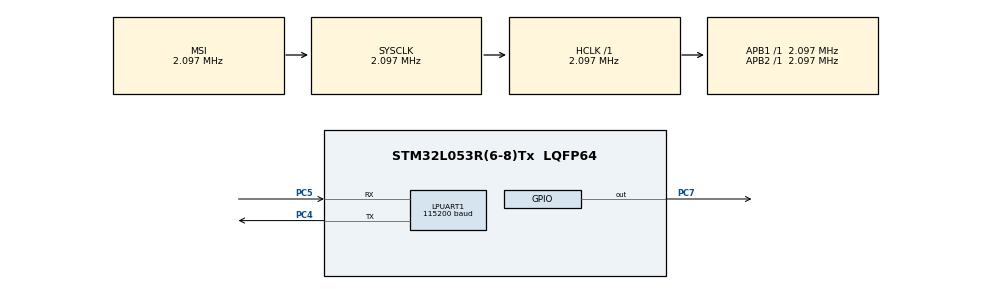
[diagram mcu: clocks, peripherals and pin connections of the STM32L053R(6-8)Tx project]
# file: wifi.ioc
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LPUART1.BaudRate=115200
LPUART1.WordLength=UART_WORDLENGTH_8B
Mcu.Family=STM32L0
Mcu.Name=STM32L053R(6-8)Tx
Mcu.Package=LQFP64
PC4.Mode=Asynchronous
PC4.Signal=LPUART1_TX
PC5.Mode=Asynchronous
PC5.Signal=LPUART1_RX
PC7.Signal=GPIO_Output
ProjectManager.HeapSize=0x200
ProjectManager.StackSize=0x400
ProjectManager.TargetToolchain=STM32CubeIDE
RCC.AHBFreq_Value=2097000
RCC.APB1Freq_Value=2097000
RCC.APB1TimFreq_Value=2097000
RCC.APB2Freq_Value=2097000
RCC.APB2TimFreq_Value=2097000
RCC.HSE_VALUE=8000000
RCC.HSI16_VALUE=16000000
RCC.HSI48_VALUE=48000000
RCC.HSI_VALUE=16000000
RCC.LSE_VALUE=32768
RCC.MSI_VALUE=2097000
RCC.SYSCLKFreq_VALUE=2097000
RCC.VCOOutputFreq_Value=48000000
board=custom

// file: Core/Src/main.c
/* USER CODE BEGIN Header */
/**
  ******************************************************************************
  * @file           : main.c
  * @brief          : Main program body
  ******************************************************************************
  * @attention
  *
  * Copyright (c) 2026 STMicroelectronics.
  * All rights reserved.
  *
  * This software is licensed under terms that can be found in the LICENSE file
  * in the root directory of this software component.
  * If no LICENSE file comes with this software, it is provided AS-IS.
  *
  ******************************************************************************
  */
/* USER CODE END Header */
#include "main.h"

/* USER CODE BEGIN Includes */
//#include <stdlib.h>
//#include <stdio.h>
//#include <string.h>
#include <stdio.h>
#include <string.h>

/* USER CODE END Includes */

UART_HandleTypeDef hlpuart1;

void SystemClock_Config(void);
static void MX_GPIO_Init(void);
static void MX_LPUART1_UART_Init(void);

/* USER CODE BEGIN 0 */
void ascii_to_decimal(const char *chars, uint8_t* int_array, uint8_t length)
{
	int i = 0;
	while (i < length){
		char character = chars[i];
		int int_val = (int)character;
		int_array[i] = int_val;
		i += 1;
		}
}

void decimal_to_ascii(uint8_t*int_array, char* ascii_array, uint8_t length)
{
	int i = 0;
	while (i < length){
		int int_val = int_array[i];
		char character = (char)int_val;
		ascii_array[i] = character;
		i += 1;
	}
}

void reset_wifi(void){
	HAL_GPIO_WritePin (GPIOC, 7, GPIO_PIN_RESET);
	HAL_Delay(1000);
	HAL_GPIO_WritePin (GPIOC, 7, GPIO_PIN_SET);
	HAL_Delay(1000);
}

void wifi_connect_to_network(void){
	//this connects to the desired network (hardcoded)
	uint8_t wifi_send_data [13];
	const char * wifi_send_data_char = "AT+CWMODE=?\r\n";//"AT+CWJAP_CUR=\"Drew\",\"12211221\"\r\r\n";

	ascii_to_decimal(wifi_send_data_char, wifi_send_data, 13);
	HAL_UART_Transmit(&hlpuart1, wifi_send_data, 13, 100000);
	//HAL_Delay();

	uint8_t wifi_rec_data_int [100];//change to correct length
	char wifi_rec_data [100]; //change to correct length
	HAL_UART_Receive(&hlpuart1, wifi_rec_data_int, 35, 1000000);
	decimal_to_ascii(wifi_rec_data_int, wifi_rec_data, 35);
	//wifi_rec_data is output (in ascii)
	//if(wifi_rec_data)
}

/* USER CODE END 0 */

int main(void)
{

  /* MCU Configuration--------------------------------------------------------*/

  /* Reset of all peripherals, Initializes the Flash interface and the Systick. */
  HAL_Init();

  /* Configure the system clock */
  SystemClock_Config();

  /* Initialize all configured peripherals */
  MX_GPIO_Init();
  MX_LPUART1_UART_Init();
  /* USER CODE BEGIN 2 */
  reset_wifi();
  wifi_connect_to_network();

  /* USER CODE END 2 */

  /* Infinite loop */
  while (1)
  {

    /* USER CODE BEGIN 3 */

	//send AT+CWLAP
	//read response
  }
  /* USER CODE END 3 */
}

void SystemClock_Config(void)
{
  RCC_OscInitTypeDef RCC_OscInitStruct = {0};
  RCC_ClkInitTypeDef RCC_ClkInitStruct = {0};
  RCC_PeriphCLKInitTypeDef PeriphClkInit = {0};

  /** Configure the main internal regulator output voltage
  */
  __HAL_PWR_VOLTAGESCALING_CONFIG(PWR_REGULATOR_VOLTAGE_SCALE1);

  /** Initializes the RCC Oscillators according to the specified parameters
  * in the RCC_OscInitTypeDef structure.
  */
  RCC_OscInitStruct.OscillatorType = RCC_OSCILLATORTYPE_MSI;
  RCC_OscInitStruct.MSIState = RCC_MSI_ON;
  RCC_OscInitStruct.MSICalibrationValue = 0;
  RCC_OscInitStruct.MSIClockRange = RCC_MSIRANGE_5;
  RCC_OscInitStruct.PLL.PLLState = RCC_PLL_NONE;
  if (HAL_RCC_OscConfig(&RCC_OscInitStruct) != HAL_OK)
  {
    Error_Handler();
  }

  /** Initializes the CPU, AHB and APB buses clocks
  */
  RCC_ClkInitStruct.ClockType = RCC_CLOCKTYPE_HCLK|RCC_CLOCKTYPE_SYSCLK
                              |RCC_CLOCKTYPE_PCLK1|RCC_CLOCKTYPE_PCLK2;
  RCC_ClkInitStruct.SYSCLKSource = RCC_SYSCLKSOURCE_MSI;
  RCC_ClkInitStruct.AHBCLKDivider = RCC_SYSCLK_DIV1;
  RCC_ClkInitStruct.APB1CLKDivider = RCC_HCLK_DIV1;
  RCC_ClkInitStruct.APB2CLKDivider = RCC_HCLK_DIV1;

  if (HAL_RCC_ClockConfig(&RCC_ClkInitStruct, FLASH_LATENCY_0) != HAL_OK)
  {
    Error_Handler();
  }
  PeriphClkInit.PeriphClockSelection = RCC_PERIPHCLK_LPUART1;
  PeriphClkInit.Lpuart1ClockSelection = RCC_LPUART1CLKSOURCE_PCLK1;
  if (HAL_RCCEx_PeriphCLKConfig(&PeriphClkInit) != HAL_OK)
  {
    Error_Handler();
  }
}

static void MX_LPUART1_UART_Init(void)
{

  hlpuart1.Instance = LPUART1;
  hlpuart1.Init.BaudRate = 115200;
  hlpuart1.Init.WordLength = UART_WORDLENGTH_8B;
  hlpuart1.Init.StopBits = UART_STOPBITS_1;
  hlpuart1.Init.Parity = UART_PARITY_NONE;
  hlpuart1.Init.Mode = UART_MODE_TX_RX;
  hlpuart1.Init.HwFlowCtl = UART_HWCONTROL_NONE;
  hlpuart1.Init.OneBitSampling = UART_ONE_BIT_SAMPLE_DISABLE;
  hlpuart1.AdvancedInit.AdvFeatureInit = UART_ADVFEATURE_NO_INIT;
  if (HAL_UART_Init(&hlpuart1) != HAL_OK)
  {
    Error_Handler();
  }

}

static void MX_GPIO_Init(void)
{
  GPIO_InitTypeDef GPIO_InitStruct = {0};

  /* GPIO Ports Clock Enable */
  __HAL_RCC_GPIOC_CLK_ENABLE();

  /*Configure GPIO pin Output Level */
  HAL_GPIO_WritePin(GPIOC, GPIO_PIN_7, GPIO_PIN_RESET);

  /*Configure GPIO pin : PC7 */
  GPIO_InitStruct.Pin = GPIO_PIN_7;
  GPIO_InitStruct.Mode = GPIO_MODE_OUTPUT_PP;
  GPIO_InitStruct.Pull = GPIO_NOPULL;
  GPIO_InitStruct.Speed = GPIO_SPEED_FREQ_LOW;
  HAL_GPIO_Init(GPIOC, &GPIO_InitStruct);

}

void Error_Handler(void)
{
  __disable_irq();
  while (1)
  {
  }
}
